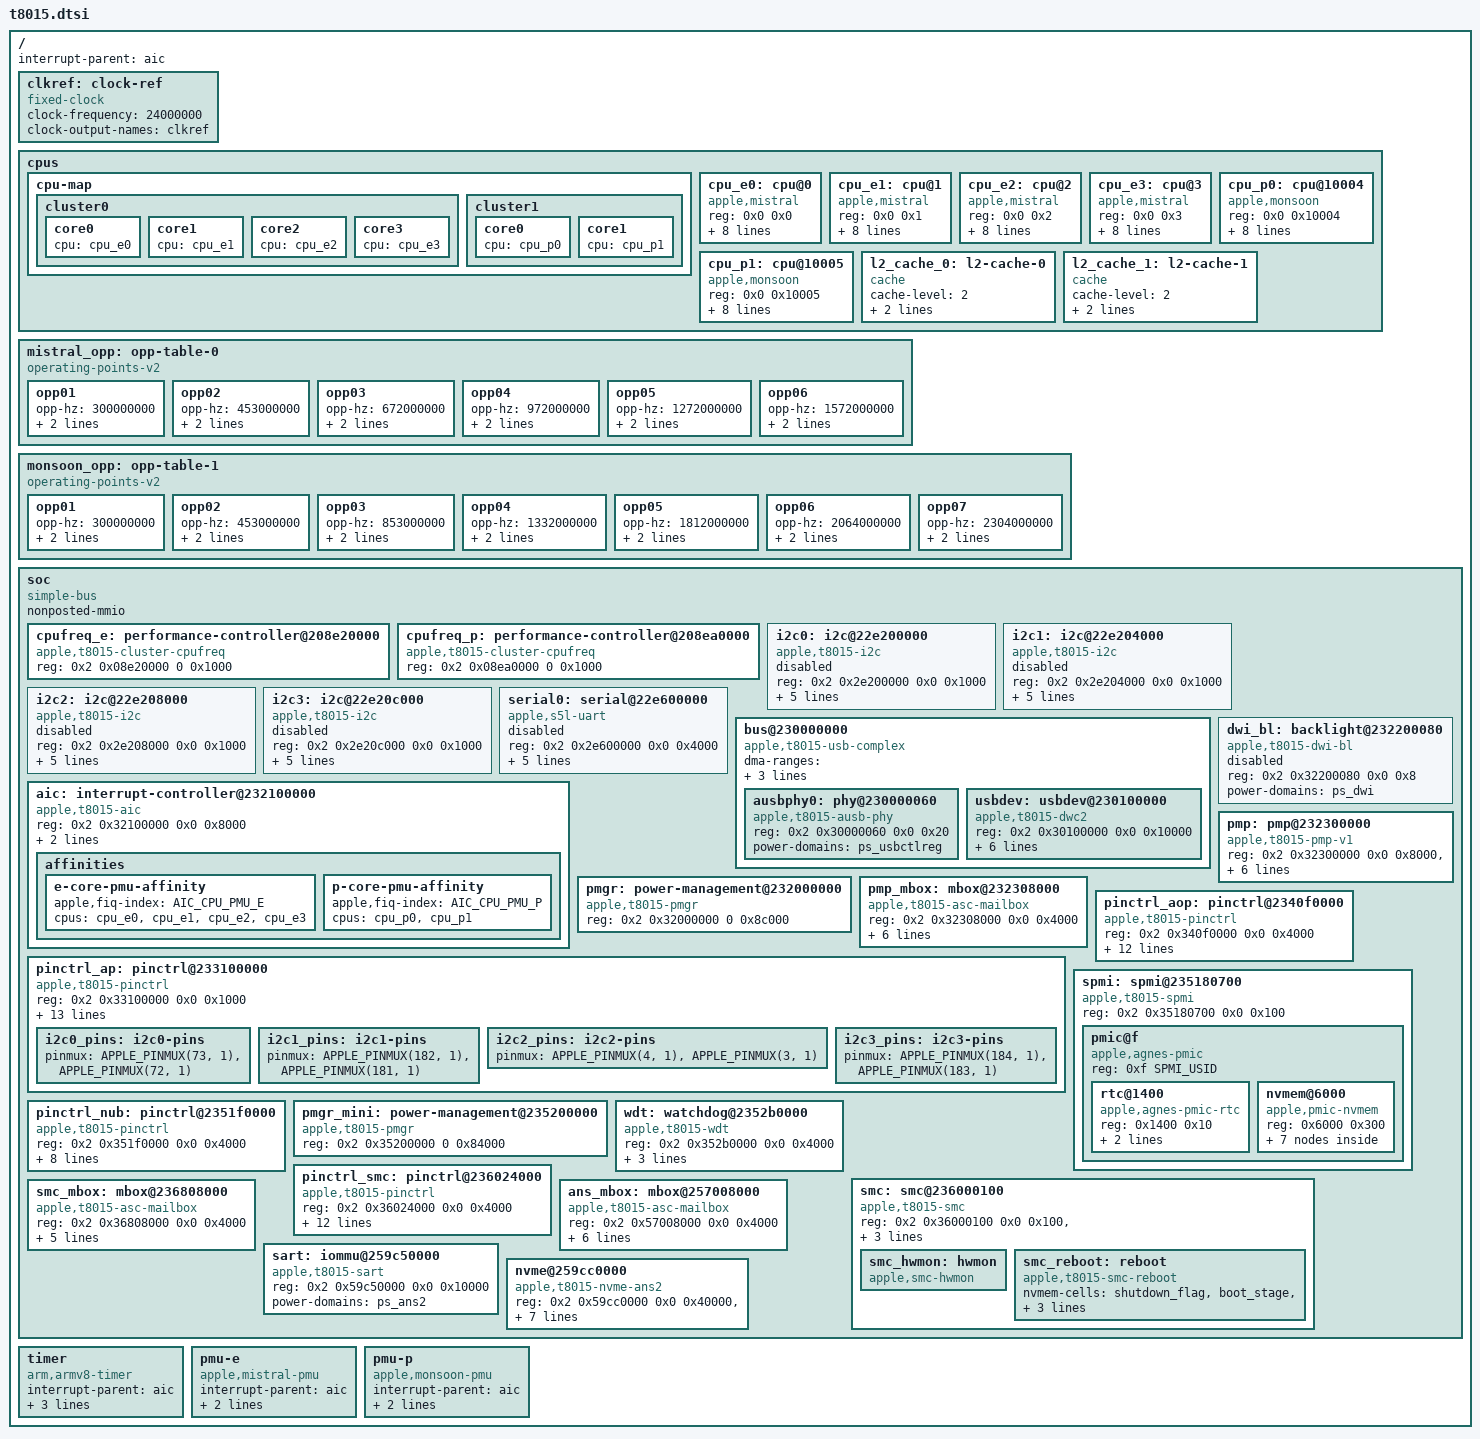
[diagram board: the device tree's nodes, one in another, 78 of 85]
// SPDX-License-Identifier: GPL-2.0+ OR MIT
/*
 * Apple T8015 "A11" SoC
 *
 * Other names: H10, "Skye"
 *
 * Copyright (c) 2022, Konrad Dybcio <konradybcio@kernel.org>
 */

#include <dt-bindings/gpio/gpio.h>
#include <dt-bindings/interrupt-controller/apple-aic.h>
#include <dt-bindings/interrupt-controller/irq.h>
#include <dt-bindings/phy/phy.h>
#include <dt-bindings/pinctrl/apple.h>
#include <dt-bindings/spmi/spmi.h>

/ {
	interrupt-parent = <&aic>;
	#address-cells = <2>;
	#size-cells = <2>;

	clkref: clock-ref {
		compatible = "fixed-clock";
		#clock-cells = <0>;
		clock-frequency = <24000000>;
		clock-output-names = "clkref";
	};

	cpus {
		#address-cells = <2>;
		#size-cells = <0>;

		cpu-map {
			cluster0 {
				core0 {
					cpu = <&cpu_e0>;
				};
				core1 {
					cpu = <&cpu_e1>;
				};
				core2 {
					cpu = <&cpu_e2>;
				};
				core3 {
					cpu = <&cpu_e3>;
				};
			};

			cluster1 {
				core0 {
					cpu = <&cpu_p0>;
				};
				core1 {
					cpu = <&cpu_p1>;
				};
			};
		};

		cpu_e0: cpu@0 {
			compatible = "apple,mistral";
			reg = <0x0 0x0>;
			cpu-release-addr = <0 0>; /* To be filled by loader */
			performance-domains = <&cpufreq_e>;
			operating-points-v2 = <&mistral_opp>;
			capacity-dmips-mhz = <633>;
			enable-method = "spin-table";
			device_type = "cpu";
			next-level-cache = <&l2_cache_0>;
			i-cache-size = <0x8000>;
			d-cache-size = <0x8000>;
		};

		cpu_e1: cpu@1 {
			compatible = "apple,mistral";
			reg = <0x0 0x1>;
			cpu-release-addr = <0 0>; /* To be filled by loader */
			performance-domains = <&cpufreq_e>;
			operating-points-v2 = <&mistral_opp>;
			capacity-dmips-mhz = <633>;
			enable-method = "spin-table";
			device_type = "cpu";
			next-level-cache = <&l2_cache_0>;
			i-cache-size = <0x8000>;
			d-cache-size = <0x8000>;
		};

		cpu_e2: cpu@2 {
			compatible = "apple,mistral";
			reg = <0x0 0x2>;
			cpu-release-addr = <0 0>; /* To be filled by loader */
			performance-domains = <&cpufreq_e>;
			operating-points-v2 = <&mistral_opp>;
			capacity-dmips-mhz = <633>;
			enable-method = "spin-table";
			device_type = "cpu";
			next-level-cache = <&l2_cache_0>;
			i-cache-size = <0x8000>;
			d-cache-size = <0x8000>;
		};

		cpu_e3: cpu@3 {
			compatible = "apple,mistral";
			reg = <0x0 0x3>;
			cpu-release-addr = <0 0>; /* To be filled by loader */
			performance-domains = <&cpufreq_e>;
			operating-points-v2 = <&mistral_opp>;
			capacity-dmips-mhz = <633>;
			enable-method = "spin-table";
			device_type = "cpu";
			next-level-cache = <&l2_cache_0>;
			i-cache-size = <0x8000>;
			d-cache-size = <0x8000>;
		};

		cpu_p0: cpu@10004 {
			compatible = "apple,monsoon";
			reg = <0x0 0x10004>;
			cpu-release-addr = <0 0>; /* To be filled by loader */
			performance-domains = <&cpufreq_p>;
			operating-points-v2 = <&monsoon_opp>;
			capacity-dmips-mhz = <1024>;
			enable-method = "spin-table";
			device_type = "cpu";
			next-level-cache = <&l2_cache_1>;
			i-cache-size = <0x10000>;
			d-cache-size = <0x10000>;
		};

		cpu_p1: cpu@10005 {
			compatible = "apple,monsoon";
			reg = <0x0 0x10005>;
			cpu-release-addr = <0 0>; /* To be filled by loader */
			performance-domains = <&cpufreq_p>;
			operating-points-v2 = <&monsoon_opp>;
			capacity-dmips-mhz = <1024>;
			enable-method = "spin-table";
			device_type = "cpu";
			next-level-cache = <&l2_cache_1>;
			i-cache-size = <0x10000>;
			d-cache-size = <0x10000>;
		};

		l2_cache_0: l2-cache-0 {
			compatible = "cache";
			cache-level = <2>;
			cache-unified;
			cache-size = <0x100000>;
		};

		l2_cache_1: l2-cache-1 {
			compatible = "cache";
			cache-level = <2>;
			cache-unified;
			cache-size = <0x800000>;
		};
	};

	mistral_opp: opp-table-0 {
		compatible = "operating-points-v2";

		opp01 {
			opp-hz = /bits/ 64 <300000000>;
			opp-level = <1>;
			clock-latency-ns = <1800>;
		};
		opp02 {
			opp-hz = /bits/ 64 <453000000>;
			opp-level = <2>;
			clock-latency-ns = <140000>;
		};
		opp03 {
			opp-hz = /bits/ 64 <672000000>;
			opp-level = <3>;
			clock-latency-ns = <105000>;
		};
		opp04 {
			opp-hz = /bits/ 64 <972000000>;
			opp-level = <4>;
			clock-latency-ns = <115000>;
		};
		opp05 {
			opp-hz = /bits/ 64 <1272000000>;
			opp-level = <5>;
			clock-latency-ns = <125000>;
		};
		opp06 {
			opp-hz = /bits/ 64 <1572000000>;
			opp-level = <6>;
			clock-latency-ns = <135000>;
		};
#if 0
		/* Not available until CPU deep sleep is implemented */
		opp07 {
			opp-hz = /bits/ 64 <1680000000>;
			opp-level = <7>;
			clock-latency-ns = <135000>;
			turbo-mode;
		};
#endif
	};

	monsoon_opp: opp-table-1 {
		compatible = "operating-points-v2";

		opp01 {
			opp-hz = /bits/ 64 <300000000>;
			opp-level = <1>;
			clock-latency-ns = <1400>;
		};
		opp02 {
			opp-hz = /bits/ 64 <453000000>;
			opp-level = <2>;
			clock-latency-ns = <140000>;
		};
		opp03 {
			opp-hz = /bits/ 64 <853000000>;
			opp-level = <3>;
			clock-latency-ns = <110000>;
		};
		opp04 {
			opp-hz = /bits/ 64 <1332000000>;
			opp-level = <4>;
			clock-latency-ns = <110000>;
		};
		opp05 {
			opp-hz = /bits/ 64 <1812000000>;
			opp-level = <5>;
			clock-latency-ns = <125000>;
		};
		opp06 {
			opp-hz = /bits/ 64 <2064000000>;
			opp-level = <6>;
			clock-latency-ns = <130000>;
		};
		opp07 {
			opp-hz = /bits/ 64 <2304000000>;
			opp-level = <7>;
			clock-latency-ns = <140000>;
		};
#if 0
		/* Not available until CPU deep sleep is implemented */
		opp08 {
			opp-hz = /bits/ 64 <2376000000>;
			opp-level = <8>;
			clock-latency-ns = <140000>;
			turbo-mode;
		};
#endif
	};

	soc {
		compatible = "simple-bus";
		#address-cells = <2>;
		#size-cells = <2>;
		nonposted-mmio;
		ranges;

		cpufreq_e: performance-controller@208e20000 {
			compatible = "apple,t8015-cluster-cpufreq", "apple,t8103-cluster-cpufreq", "apple,cluster-cpufreq";
			reg = <0x2 0x08e20000 0 0x1000>;
			#performance-domain-cells = <0>;
		};

		cpufreq_p: performance-controller@208ea0000 {
			compatible = "apple,t8015-cluster-cpufreq", "apple,t8103-cluster-cpufreq", "apple,cluster-cpufreq";
			reg = <0x2 0x08ea0000 0 0x1000>;
			#performance-domain-cells = <0>;
		};

		i2c0: i2c@22e200000 {
			compatible = "apple,t8015-i2c", "apple,i2c";
			reg = <0x2 0x2e200000 0x0 0x1000>;
			clocks = <&clkref>;
			interrupt-parent = <&aic>;
			interrupts = <AIC_IRQ 304 IRQ_TYPE_LEVEL_HIGH>;
			pinctrl-0 = <&i2c0_pins>;
			pinctrl-names = "default";
			power-domains = <&ps_i2c0>;
			#address-cells = <1>;
			#size-cells = <0>;
			status = "disabled";
		};

		i2c1: i2c@22e204000 {
			compatible = "apple,t8015-i2c", "apple,i2c";
			reg = <0x2 0x2e204000 0x0 0x1000>;
			clocks = <&clkref>;
			interrupt-parent = <&aic>;
			interrupts = <AIC_IRQ 305 IRQ_TYPE_LEVEL_HIGH>;
			pinctrl-0 = <&i2c1_pins>;
			pinctrl-names = "default";
			power-domains = <&ps_i2c1>;
			#address-cells = <1>;
			#size-cells = <0>;
			status = "disabled";
		};

		i2c2: i2c@22e208000 {
			compatible = "apple,t8015-i2c", "apple,i2c";
			reg = <0x2 0x2e208000 0x0 0x1000>;
			clocks = <&clkref>;
			interrupt-parent = <&aic>;
			interrupts = <AIC_IRQ 306 IRQ_TYPE_LEVEL_HIGH>;
			pinctrl-0 = <&i2c2_pins>;
			pinctrl-names = "default";
			power-domains = <&ps_i2c2>;
			#address-cells = <1>;
			#size-cells = <0>;
			status = "disabled";
		};

		i2c3: i2c@22e20c000 {
			compatible = "apple,t8015-i2c", "apple,i2c";
			reg = <0x2 0x2e20c000 0x0 0x1000>;
			clocks = <&clkref>;
			interrupt-parent = <&aic>;
			interrupts = <AIC_IRQ 307 IRQ_TYPE_LEVEL_HIGH>;
			pinctrl-0 = <&i2c3_pins>;
			pinctrl-names = "default";
			power-domains = <&ps_i2c3>;
			#address-cells = <1>;
			#size-cells = <0>;
			status = "disabled";
		};

		serial0: serial@22e600000 {
			compatible = "apple,s5l-uart";
			reg = <0x2 0x2e600000 0x0 0x4000>;
			reg-io-width = <4>;
			interrupt-parent = <&aic>;
			interrupts = <AIC_IRQ 282 IRQ_TYPE_LEVEL_HIGH>;
			/* Use the bootloader-enabled clocks for now. */
			clocks = <&clkref>, <&clkref>;
			clock-names = "uart", "clk_uart_baud0";
			power-domains = <&ps_uart0>;
			status = "disabled";
		};

		bus@230000000 {
			compatible = "apple,t8015-usb-complex", "simple-pm-bus";
			#address-cells = <2>;
			#size-cells = <2>;
			dma-ranges = <0x0 0x00000000 0x8 0x00000000 0x1 0x00000000>;
			ranges;

			reg = <0x2 0x30000000 0x0 0x60>;
			power-domains = <&ps_usb>;

			ausbphy0: phy@230000060 {
				compatible = "apple,t8015-ausb-phy", "apple,ausb-phy";
				reg = <0x2 0x30000060 0x0 0x20>;
				power-domains = <&ps_usbctlreg>;
				#phy-cells = <1>;
				/* Tunables to be filled by loader */
			};

			usbdev: usbdev@230100000 {
				compatible = "apple,t8015-dwc2", "apple,dwc2";
				reg = <0x2 0x30100000 0x0 0x10000>;
				interrupts = <AIC_IRQ 324 IRQ_TYPE_LEVEL_HIGH>;
				clocks = <&clkref>;
				clock-names = "otg";
				phys = <&ausbphy0 PHY_TYPE_USB2>;
				phy-names = "usb2-phy";
				power-domains = <&ps_usb2dev>;
				resets = <&ps_usb2dev>;
				dr_mode = "peripheral";
			};

#if 0
			ehci0: usb-ehci@230200000 {
				compatible = "apple,t8015-ehci", "generic-ehci";
				reg = <0x2 0x30200000 0x0 0x10000>;
				interrupts = <AIC_IRQ 319 IRQ_TYPE_LEVEL_HIGH>;
				power-domains = <&ps_usb2host0>;
			};

			ohci0: usb-ohci@230300000 {
				compatible = "apple,t8015-ohci", "generic-ohci";
				reg = <0x2 0x30300000 0x0 0x10000>;
				interrupts = <AIC_IRQ 320 IRQ_TYPE_LEVEL_HIGH>;
				power-domains = <&ps_usb2host0_ohci>;
			};

			ehci1: usb-ehci@230400000 {
				compatible = "apple,t8015-ehci", "generic-ehci";
				reg = <0x2 0x30400000 0x0 0x10000>;
				interrupts = <AIC_IRQ 321 IRQ_TYPE_LEVEL_HIGH>;
				power-domains = <&ps_usb2host1>;
			};
#endif
		};

		aic: interrupt-controller@232100000 {
			compatible = "apple,t8015-aic", "apple,aic";
			reg = <0x2 0x32100000 0x0 0x8000>;
			#interrupt-cells = <3>;
			interrupt-controller;
			power-domains = <&ps_aic>;

			affinities {
				e-core-pmu-affinity {
					apple,fiq-index = <AIC_CPU_PMU_E>;
					cpus = <&cpu_e0 &cpu_e1 &cpu_e2 &cpu_e3>;
				};

				p-core-pmu-affinity {
					apple,fiq-index = <AIC_CPU_PMU_P>;
					cpus = <&cpu_p0 &cpu_p1>;
				};
			};
		};

		pmgr: power-management@232000000 {
			compatible = "apple,t8015-pmgr", "apple,pmgr", "syscon", "simple-mfd";
			#address-cells = <1>;
			#size-cells = <1>;

			reg = <0x2 0x32000000 0 0x8c000>;
		};

		dwi_bl: backlight@232200080 {
			compatible = "apple,t8015-dwi-bl", "apple,dwi-bl";
			reg = <0x2 0x32200080 0x0 0x8>;
			power-domains = <&ps_dwi>;
			status = "disabled";
		};

		pmp: pmp@232300000 {
			compatible = "apple,t8015-pmp-v1";
			reg = <0x2 0x32300000 0x0 0x8000>,
			      <0x2 0x32400000 0x0 0x10000>,
			      <0x2 0x32500000 0x0 0x20000>;
			reg-names = "akf", "control", "sram";
			mboxes = <&pmp_mbox>;
			mbox-names = "mbox";
			power-domains = <&ps_pmp>, <&ps_pms_sram>;
			power-domain-names = "pmp", "sram";
			firmware-name = "apple/pmp-t8015.bin";
		};

		pmp_mbox: mbox@232308000 {
			compatible = "apple,t8015-asc-mailbox";
			reg = <0x2 0x32308000 0x0 0x4000>;
			interrupt-parent = <&aic>;
			interrupts = <AIC_IRQ 229 IRQ_TYPE_LEVEL_HIGH>,
				     <AIC_IRQ 230 IRQ_TYPE_LEVEL_HIGH>,
				     <AIC_IRQ 231 IRQ_TYPE_LEVEL_HIGH>,
				     <AIC_IRQ 232 IRQ_TYPE_LEVEL_HIGH>;
			interrupt-names = "send-empty", "send-not-empty",
				"recv-empty", "recv-not-empty";
			#mbox-cells = <0>;
			power-domains = <&ps_pmp>;
		};


		pinctrl_ap: pinctrl@233100000 {
			compatible = "apple,t8015-pinctrl", "apple,pinctrl";
			reg = <0x2 0x33100000 0x0 0x1000>;
			power-domains = <&ps_gpio>;

			gpio-controller;
			#gpio-cells = <2>;
			gpio-ranges = <&pinctrl_ap 0 0 223>;
			apple,npins = <223>;

			interrupt-controller;
			#interrupt-cells = <2>;
			interrupt-parent = <&aic>;
			interrupts = <AIC_IRQ 50 IRQ_TYPE_LEVEL_HIGH>,
				     <AIC_IRQ 51 IRQ_TYPE_LEVEL_HIGH>,
				     <AIC_IRQ 52 IRQ_TYPE_LEVEL_HIGH>,
				     <AIC_IRQ 53 IRQ_TYPE_LEVEL_HIGH>,
				     <AIC_IRQ 54 IRQ_TYPE_LEVEL_HIGH>,
				     <AIC_IRQ 55 IRQ_TYPE_LEVEL_HIGH>,
				     <AIC_IRQ 56 IRQ_TYPE_LEVEL_HIGH>;

			i2c0_pins: i2c0-pins {
				pinmux = <APPLE_PINMUX(73, 1)>,
					 <APPLE_PINMUX(72, 1)>;
			};

			i2c1_pins: i2c1-pins {
				pinmux = <APPLE_PINMUX(182, 1)>,
					 <APPLE_PINMUX(181, 1)>;
			};

			i2c2_pins: i2c2-pins {
				pinmux = <APPLE_PINMUX(4, 1)>,
					 <APPLE_PINMUX(3, 1)>;
			};

			i2c3_pins: i2c3-pins {
				pinmux = <APPLE_PINMUX(184, 1)>,
					 <APPLE_PINMUX(183, 1)>;
			};
		};

		pinctrl_aop: pinctrl@2340f0000 {
			compatible = "apple,t8015-pinctrl", "apple,pinctrl";
			reg = <0x2 0x340f0000 0x0 0x4000>;

			gpio-controller;
			#gpio-cells = <2>;
			gpio-ranges = <&pinctrl_aop 0 0 49>;
			apple,npins = <49>;

			interrupt-controller;
			#interrupt-cells = <2>;
			interrupt-parent = <&aic>;
			interrupts = <AIC_IRQ 135 IRQ_TYPE_LEVEL_HIGH>,
				     <AIC_IRQ 136 IRQ_TYPE_LEVEL_HIGH>,
				     <AIC_IRQ 137 IRQ_TYPE_LEVEL_HIGH>,
				     <AIC_IRQ 138 IRQ_TYPE_LEVEL_HIGH>,
				     <AIC_IRQ 139 IRQ_TYPE_LEVEL_HIGH>,
				     <AIC_IRQ 140 IRQ_TYPE_LEVEL_HIGH>,
				     <AIC_IRQ 141 IRQ_TYPE_LEVEL_HIGH>;
		};

		spmi: spmi@235180700 {
			compatible = "apple,t8015-spmi", "apple,t8103-spmi";
			reg = <0x2 0x35180700 0x0 0x100>;
			#address-cells = <2>;
			#size-cells = <0>;

			pmic@f {
				compatible = "apple,agnes-pmic", "apple,spmi-pmic";
				reg = <0xf SPMI_USID>;
				#address-cells = <1>;
				#size-cells = <1>;

				rtc@1400 {
					compatible = "apple,agnes-pmic-rtc", "apple,antigua-pmic-rtc";
					reg = <0x1400 0x10>;
					nvmem-cells = <&rtc_offset>;
					nvmem-cell-names = "rtc_offset";
				};

				nvmem@6000 {
					compatible = "apple,pmic-nvmem";
					reg = <0x6000 0x300>;

					nvmem-layout {
						compatible = "fixed-layout";
						#address-cells = <1>;
						#size-cells = <1>;

						boot_stage: boot-stage@1 {
							reg = <0x1 0x1>;
						};

						boot_error_count: boot-error-count@2,0 {
							reg = <0x2 0x1>;
							bits = <0 4>;
						};

						panic_count: panic-count@2,4 {
							reg = <0x2 0x1>;
							bits = <4 4>;
						};

						boot_error_stage: boot-error-stage@3 {
							reg = <0x3 0x1>;
						};

						rtc_offset: rtc-offset@4 {
							reg = <0x4 0x4>;
						};

						shutdown_flag: shutdown-flag@f {
							reg = <0xf 0x1>;
						};
					};
				};
			};
		};

		pinctrl_nub: pinctrl@2351f0000 {
			compatible = "apple,t8015-pinctrl", "apple,pinctrl";
			reg = <0x2 0x351f0000 0x0 0x4000>;

			gpio-controller;
			#gpio-cells = <2>;
			gpio-ranges = <&pinctrl_nub 0 0 8>;
			apple,npins = <8>;

			interrupt-controller;
			#interrupt-cells = <2>;
			interrupt-parent = <&aic>;
			interrupts = <AIC_IRQ 168 IRQ_TYPE_LEVEL_HIGH>,
				     <AIC_IRQ 169 IRQ_TYPE_LEVEL_HIGH>,
				     <AIC_IRQ 170 IRQ_TYPE_LEVEL_HIGH>;
		};

		pmgr_mini: power-management@235200000 {
			compatible = "apple,t8015-pmgr", "apple,pmgr", "syscon", "simple-mfd";
			#address-cells = <1>;
			#size-cells = <1>;

			reg = <0x2 0x35200000 0 0x84000>;
		};

		wdt: watchdog@2352b0000 {
			compatible = "apple,t8015-wdt", "apple,wdt";
			reg = <0x2 0x352b0000 0x0 0x4000>;
			clocks = <&clkref>;
			interrupt-parent = <&aic>;
			interrupts = <AIC_IRQ 172 IRQ_TYPE_LEVEL_HIGH>;
		};

		smc: smc@236000100 {
			compatible = "apple,t8015-smc", "apple,t8103-smc";
			reg = <0x2 0x36000100 0x0 0x100>,
				<0x2 0x36e00000 0x0 0x40000>;
			reg-names = "smc", "sram";
			mboxes = <&smc_mbox>;
			power-domains = <&ps_smc_cpu>;

			smc_hwmon: hwmon {
				compatible = "apple,smc-hwmon";
			};

			smc_reboot: reboot {
				compatible = "apple,t8015-smc-reboot";
				nvmem-cells = <&shutdown_flag>, <&boot_stage>,
					<&boot_error_count>, <&panic_count>;
				nvmem-cell-names = "shutdown_flag", "boot_stage",
					"boot_error_count", "panic_count";
				/* To be filled by loader */
			};
		};

		pinctrl_smc: pinctrl@236024000 {
			compatible = "apple,t8015-pinctrl", "apple,pinctrl";
			reg = <0x2 0x36024000 0x0 0x4000>;

			gpio-controller;
			#gpio-cells = <2>;
			gpio-ranges = <&pinctrl_smc 0 0 6>;
			apple,npins = <6>;

			interrupt-controller;
			#interrupt-cells = <2>;
			interrupt-parent = <&aic>;
			interrupts = <AIC_IRQ 199 IRQ_TYPE_LEVEL_HIGH>,
				     <AIC_IRQ 200 IRQ_TYPE_LEVEL_HIGH>,
				     <AIC_IRQ 201 IRQ_TYPE_LEVEL_HIGH>,
				     <AIC_IRQ 202 IRQ_TYPE_LEVEL_HIGH>,
				     <AIC_IRQ 203 IRQ_TYPE_LEVEL_HIGH>,
				     <AIC_IRQ 204 IRQ_TYPE_LEVEL_HIGH>,
				     <AIC_IRQ 205 IRQ_TYPE_LEVEL_HIGH>;
		};

		smc_mbox: mbox@236808000 {
			compatible = "apple,t8015-asc-mailbox";
			reg = <0x2 0x36808000 0x0 0x4000>;
			interrupt-parent = <&aic>;
			interrupts = <AIC_IRQ 209 IRQ_TYPE_LEVEL_HIGH>,
				<AIC_IRQ 210 IRQ_TYPE_LEVEL_HIGH>,
				<AIC_IRQ 211 IRQ_TYPE_LEVEL_HIGH>,
				<AIC_IRQ 212 IRQ_TYPE_LEVEL_HIGH>;
			interrupt-names = "send-empty", "send-not-empty",
				"recv-empty", "recv-not-empty";
			#mbox-cells = <0>;
		};

		ans_mbox: mbox@257008000 {
			compatible = "apple,t8015-asc-mailbox";
			reg = <0x2 0x57008000 0x0 0x4000>;
			interrupt-parent = <&aic>;
			interrupts = <AIC_IRQ 265 IRQ_TYPE_LEVEL_HIGH>,
				<AIC_IRQ 266 IRQ_TYPE_LEVEL_HIGH>,
				<AIC_IRQ 267 IRQ_TYPE_LEVEL_HIGH>,
				<AIC_IRQ 268 IRQ_TYPE_LEVEL_HIGH>;
			interrupt-names = "send-empty", "send-not-empty",
				"recv-empty", "recv-not-empty";
			#mbox-cells = <0>;
			power-domains = <&ps_ans2>;
		};

		sart: iommu@259c50000 {
			compatible = "apple,t8015-sart";
			reg = <0x2 0x59c50000 0x0 0x10000>;
			power-domains = <&ps_ans2>;
		};

		nvme@259cc0000 {
			compatible = "apple,t8015-nvme-ans2";
			reg = <0x2 0x59cc0000 0x0 0x40000>,
				<0x2 0x59d20000 0x0 0x2000>;
			reg-names = "nvme", "ans";
			interrupt-parent = <&aic>;
			interrupts = <AIC_IRQ 270 IRQ_TYPE_LEVEL_HIGH>;
			mboxes = <&ans_mbox>;
			apple,sart = <&sart>;
			power-domains = <&ps_ans2>, <&ps_pcie>;
			power-domain-names = "ans", "apcie0";
			resets = <&ps_ans2>;
		};
	};

	timer {
		compatible = "arm,armv8-timer";
		interrupt-parent = <&aic>;
		interrupt-names = "phys", "virt";
		/* Note that A11 doesn't actually have a hypervisor (EL2 is not implemented). */
		interrupts = <AIC_FIQ AIC_TMR_GUEST_PHYS IRQ_TYPE_LEVEL_HIGH>,
			     <AIC_FIQ AIC_TMR_GUEST_VIRT IRQ_TYPE_LEVEL_HIGH>;
	};

	pmu-e {
		compatible = "apple,mistral-pmu";
		interrupt-parent = <&aic>;
		interrupts = <AIC_FIQ AIC_CPU_PMU_E IRQ_TYPE_LEVEL_HIGH>;
	};

	pmu-p {
		compatible = "apple,monsoon-pmu";
		interrupt-parent = <&aic>;
		interrupts = <AIC_FIQ AIC_CPU_PMU_P IRQ_TYPE_LEVEL_HIGH>;
	};
};

#include "t8015-pmgr.dtsi"
